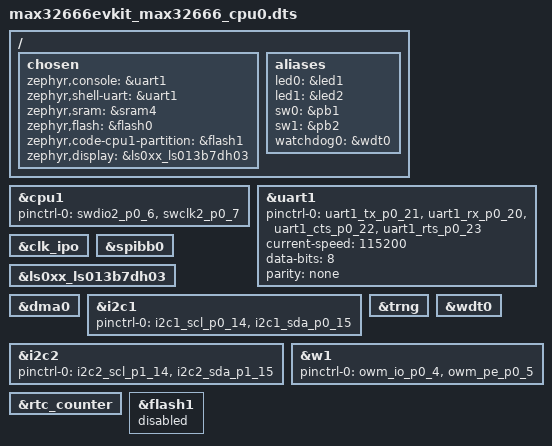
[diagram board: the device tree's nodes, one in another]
/*
 * Copyright (c) 2024 Analog Devices, Inc.
 *
 * SPDX-License-Identifier: Apache-2.0
 */

#include "max32666evkit.dtsi"

/ {
	chosen {
		zephyr,console = &uart1;
		zephyr,shell-uart = &uart1;
		zephyr,sram = &sram4;
		zephyr,flash = &flash0;
		zephyr,code-cpu1-partition = &flash1;
		zephyr,display = &ls0xx_ls013b7dh03;
	};

	/* These aliases are provided for compatibility with samples */
	aliases {
		led0 = &led1;
		led1 = &led2;
		sw0 = &pb1;
		sw1 = &pb2;
		watchdog0 = &wdt0;
	};
};

/* Set up SWD of CPU1 using the PORT0 6 & 7 pins exposed on JH1 */
&cpu1 {
	pinctrl-0 = <&swdio2_p0_6 &swclk2_p0_7>;
	pinctrl-names = "default";
};

&uart1 {
	pinctrl-0 = <&uart1_tx_p0_21 &uart1_rx_p0_20 &uart1_cts_p0_22 &uart1_rts_p0_23>;
	pinctrl-names = "default";
	current-speed = <115200>;
	data-bits = <8>;
	parity = "none";
	status = "okay";
};

&clk_ipo {
	status = "okay";
};

&spibb0 {
	status = "okay";
};

&ls0xx_ls013b7dh03 {
	status = "okay";
};

&dma0 {
	status = "okay";
};

&i2c1 {
	status = "okay";
	pinctrl-0 = <&i2c1_scl_p0_14 &i2c1_sda_p0_15>;
	pinctrl-names = "default";
};

&i2c2 {
	status = "okay";
	pinctrl-0 = <&i2c2_scl_p1_14 &i2c2_sda_p1_15>;
	pinctrl-names = "default";
};

&trng {
	status = "okay";
};

&wdt0 {
	status = "okay";
};

&w1 {
	pinctrl-0 = <&owm_io_p0_4 &owm_pe_p0_5>;
	pinctrl-names = "default";
};

&rtc_counter {
	status = "okay";
};

/* Ensure we don't attempt to access flash instance used by CPU1 */
&flash1 {
	status = "disabled";
};
